# ADuCM320i register map
Vendor: Analog Devices Inc.; Series: ARMCM3; File version: 1.0
CPU: CM3 r2p1, little endian, no MPU, no FPU, 3 interrupt priority bits
Registers are 16-bit, read-write, no defined reset value unless marked. A register's access mark holds for its fields unless they carry their own. Offsets are from the block's base; [hi:lo] are bit positions; {n}, {i} and the like mark numbered series.

## ADC — Analog to Digital converter
Base 0x40082170
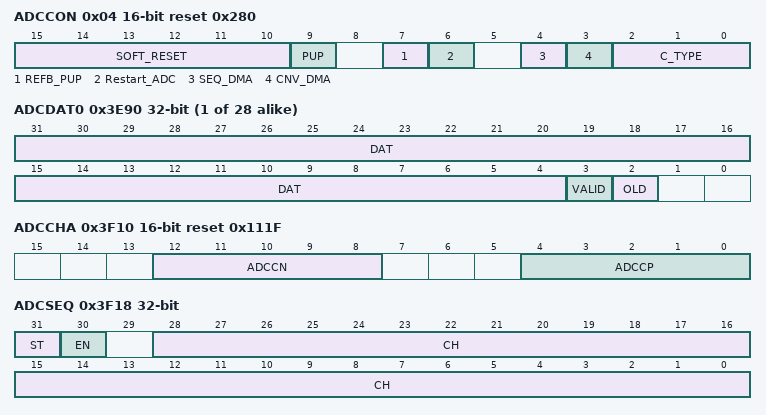
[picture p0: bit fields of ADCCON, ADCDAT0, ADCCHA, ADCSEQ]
0x04 ADCCON reset 0x280 (reset mask 0x0) — ADC Configuration
  [15:10] SOFT_RESET wo range 0x00000000..0x0000003F — software reset ADC
  [9] PUP range 0x00000000..0x00000001 — ADC power up
  [7] REFB_PUP range 0x00000000..0x00000001 — ADC reference buffer power up
  [6] Restart_ADC wo range 0x00000000..0x00000001 — Restart ADC, reset Analog Part of ADC
  [4] SEQ_DMA range 0x00000000..0x00000001 — DMA request enable for ADC sequence conversion
  [3] CNV_DMA range 0x00000000..0x00000001 — DMA request enable for ADC non-sequence conversion
  [2:0] C_TYPE — ADC conversion type
    0=NO (No conversion); 1=DIO (pin starts conversion (P2.4)); 2=SINGLE (Single conversion); 3=CONT (Continuous conversion (use this mode for the sequencer)); 4=PLA (conversion)
{0x3E90+4i} ADCDAT{i} (i=0..27) 32-bit ro — ADCx Data and flags
  [31:4] DAT range 0x00000000..0x0FFFFFFF — ADCx data
  [3] VALID — Flag indicating if data is valid.
    0=CLR (Data is Invalid); 1=SET (Data is Valid)
  [2] OLD — Flag data has already been read.
    0=CLR (Last data has not been read); 1=SET (Last data already read)
0x3F10 ADCCHA reset 0x111F (reset mask 0x0) — ADC Channel Select
  [12:8] ADCCN — Selects channel for ADC negative input
    {v}=AIN{v} (v=0..15); 16=VREFP_NADC (: Connect ADC_REFP to negative input.); 17=VREFN_NADC (: Connect ADC_REFN to negative input. Use This setting for single ended measurements.); 18=AGND; 19=PGND
  [4:0] ADCCP — Select ADC channel
    {v}=AIN{v} (v=0..15); 22=TEMP_SENSOR; 23=VREFP_PADC (: Connect ADC_REFP to positive input. Note: This pin should not be measured relative to AGND. This selection is intended for measuring the differential voltage between the negative input and ADC_REFP.); 24=PVDD_IDAC2 (: Use this to measure the PVDD supply voltage for IDAC2); 25=IOVDD_2 (: Use this to measure half of the IOVDD supply voltage); 26=AVDD_2 (: Use this to measure half of the AVDD supply voltage.); 27=VREFN_PADC (: Connect ADC_REFN to positive input.)
0x3F18 ADCSEQ 32-bit — ADC Sequencer Control
  [31] ST wo range 0x00000000..0x00000001 — Sequence restart, used to force sequence to start at first channel when sequence is working
  [30] EN wo range 0x00000000..0x00000001 — Sequence enable
  [28:0] CH range 0x00000000..0x1FFFFFFF — Select channels included in sequence operation.
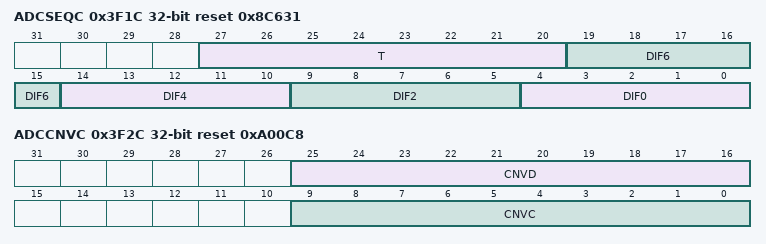
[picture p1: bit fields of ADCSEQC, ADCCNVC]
0x3F1C ADCSEQC 32-bit reset 0x8C631 (reset mask 0x0) — ADC Sequencer Configuration
  [27:20] T range 0x00000000..0x000000FF — Define programmable delay of 0 to 254 between sequences. A delay 255 will cause a halt after one sequence.
  [19:15] DIF6 range 0x00000000..0x0000001F — Selects differential mode negative input for AIN6 in the sequence.
  [14:10] DIF4 range 0x00000000..0x0000001F — Selects differential mode negative input for AIN4 in the sequence.
  [9:5] DIF2 range 0x00000000..0x0000001F — Selects differential mode negative input for AIN2 in the sequence.
  [4:0] DIF0 range 0x00000000..0x0000001F — Selects differential mode negative input for AIN0 in the sequence.
0x3F20 ADCGN reset 0x2000 (reset mask 0x0) — User gain adjust
  [13:0] GN range 0x00000000..0x00003FFF — User gain register
0x3F24 ADCOF 14-bit reset 0x2000 (reset mask 0x0) — User offset adjust
  [13:0] OF range 0x00000000..0x00003FFF — User offset register
0x3F28 ADCCMP 18-bit — Digital comparator configuration
  [17:2] THR range 0x00000000..0x0000FFFF — Digital compare threshold
  [1] DIR — Select digital comparator direction
    0=DIS (ADCTH less than channel 4 data); 1=EN (ADCTH larger than channel 4 data)
  [0] EN — Digital comparator enable
    0=DIS (Disable); 1=EN (Enable)
0x3F2C ADCCNVC 32-bit reset 0xA00C8 (reset mask 0x0) — ADC conversion configuration
  [25:16] CNVD range 0x00000000..0x000003FF — Configure ADC Acquisition time and sampling time
  [9:0] CNVC range 0x00000000..0x000003FF — Configure Conversion frequency
